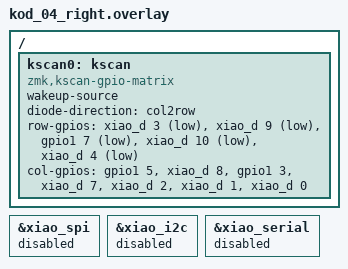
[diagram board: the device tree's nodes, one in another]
/*
 * Copyright (c) 2024 kodomari
 * SPDX-License-Identifier: MIT
 */

#include "kod_04.dtsi"

&xiao_spi { status = "disabled"; };
&xiao_i2c { status = "disabled"; };
&xiao_serial { status = "disabled"; };

/ {
    kscan0: kscan {
        compatible = "zmk,kscan-gpio-matrix";
        wakeup-source;
diode-direction = "col2row";

row-gpios
  = <&xiao_d 3  (GPIO_ACTIVE_LOW | GPIO_PULL_UP)>
  , <&xiao_d 9  (GPIO_ACTIVE_LOW | GPIO_PULL_UP)>
  , <&gpio1 7   (GPIO_ACTIVE_LOW | GPIO_PULL_UP)>
  , <&xiao_d 10 (GPIO_ACTIVE_LOW | GPIO_PULL_UP)>
  , <&xiao_d 4  (GPIO_ACTIVE_LOW | GPIO_PULL_UP)>
  ;

col-gpios
  = <&gpio1 5 GPIO_ACTIVE_HIGH>
  , <&xiao_d 8 GPIO_ACTIVE_HIGH>
  , <&gpio1 3 GPIO_ACTIVE_HIGH>
  , <&xiao_d 7 GPIO_ACTIVE_HIGH>
  , <&xiao_d 2 GPIO_ACTIVE_HIGH>
  , <&xiao_d 1 GPIO_ACTIVE_HIGH>
  , <&xiao_d 0 GPIO_ACTIVE_HIGH>
  ;
};
};


// トラックポイントはコメントアウト（後で追加）
// &input_ps2 {
//     status = "okay";
//     scl-gpios = <&gpio0 XX GPIO_ACTIVE_HIGH>;  // CLK (後で決定)
//     sda-gpios = <&gpio0 YY GPIO_ACTIVE_HIGH>;  // DATA (後で決定)
// };
